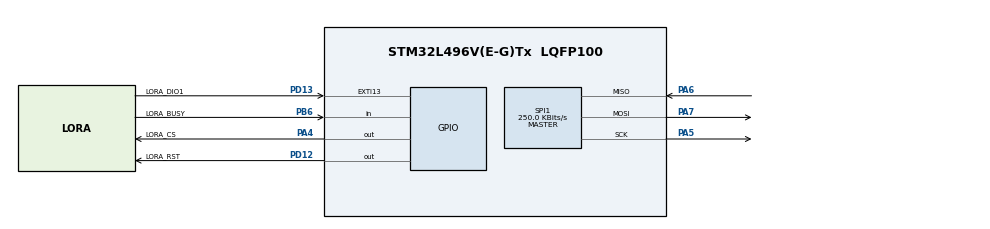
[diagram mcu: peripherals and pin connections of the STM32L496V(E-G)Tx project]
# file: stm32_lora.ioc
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FREERTOS.Tasks01=OBCTask,24,2048,StartOBCTask,Default,NULL,Dynamic,NULL,NULL
FREERTOS.configTOTAL_HEAP_SIZE=65536
FREERTOS.configUSE_NEWLIB_REENTRANT=1
Mcu.Family=STM32L4
Mcu.Name=STM32L496V(E-G)Tx
Mcu.Package=LQFP100
NVIC.EXTI15_10_IRQn=true\:5\:0\:false\:false\:true\:true\:true\:true\:true
NVIC.PriorityGroup=NVIC_PRIORITYGROUP_4
NVIC.TIM6_DAC_IRQn=true\:15\:0\:false\:false\:true\:false\:false\:true\:true
NVIC.TimeBase=TIM6_DAC_IRQn
NVIC.TimeBaseIP=TIM6
PA13\ (JTMS/SWDIO).Mode=Trace_Asynchronous_SW
PA13\ (JTMS/SWDIO).Signal=SYS_JTMS-SWDIO
PA14\ (JTCK/SWCLK).Mode=Trace_Asynchronous_SW
PA14\ (JTCK/SWCLK).Signal=SYS_JTCK-SWCLK
PA4.GPIO_Label=LORA_CS
PA4.GPIO_Speed=GPIO_SPEED_FREQ_HIGH
PA4.PinState=GPIO_PIN_SET
PA4.Signal=GPIO_Output
PA5.Mode=Full_Duplex_Master
PA5.Signal=SPI1_SCK
PA6.Mode=Full_Duplex_Master
PA6.Signal=SPI1_MISO
PA7.Mode=Full_Duplex_Master
PA7.Signal=SPI1_MOSI
PB3\ (JTDO/TRACESWO).Mode=Trace_Asynchronous_SW
PB3\ (JTDO/TRACESWO).Signal=SYS_JTDO-SWO
PB6.GPIO_Label=LORA_BUSY
PB6.Signal=GPIO_Input
PD12.GPIO_Label=LORA_RST
PD12.PinState=GPIO_PIN_SET
PD12.Signal=GPIO_Output
PD13.GPIO_Label=LORA_DIO1
PD13.Signal=GPXTI13
ProjectManager.HeapSize=0x200
ProjectManager.StackSize=0x400
ProjectManager.TargetToolchain=STM32CubeIDE
RCC.HSE_VALUE=8000000
RCC.HSI48_VALUE=48000000
RCC.HSI_VALUE=16000000
RCC.LSE_VALUE=32768
RCC.MSI_VALUE=4000000
RCC.VCOOutputFreq_Value=32000000
SPI1.BaudRatePrescaler=SPI_BAUDRATEPRESCALER_16
SPI1.CLKPhase=SPI_PHASE_1EDGE
SPI1.CalculateBaudRate=250.0 KBits/s
SPI1.DataSize=SPI_DATASIZE_8BIT
SPI1.Direction=SPI_DIRECTION_2LINES
SPI1.Mode=SPI_MODE_MASTER
SPI1.NSSPMode=SPI_NSS_PULSE_DISABLE
SPI1.VirtualType=VM_MASTER
VP_FREERTOS_VS_CMSIS_V2.Mode=CMSIS_V2
VP_SYS_VS_tim6.Mode=TIM6
board=custom

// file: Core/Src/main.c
/* USER CODE BEGIN Header */
/**
  ******************************************************************************
  * @file           : main.c
  * @brief          : Main program body
  ******************************************************************************
  * @attention
  *
  * Copyright (c) 2026 STMicroelectronics.
  * All rights reserved.
  *
  * This software is licensed under terms that can be found in the LICENSE file
  * in the root directory of this software component.
  * If no LICENSE file comes with this software, it is provided AS-IS.
  *
  ******************************************************************************
  */
/* USER CODE END Header */
#include "main.h"
#include "cmsis_os.h"

/* USER CODE BEGIN Includes */
#include "COMMS.h"
/* USER CODE END Includes */

SPI_HandleTypeDef hspi1;

/* Definitions for OBCTask */
osThreadId_t OBCTaskHandle;
const osThreadAttr_t OBCTask_attributes = {
  .name = "OBCTask",
  .stack_size = 2048 * 4,
  .priority = (osPriority_t) osPriorityNormal,
};

void SystemClock_Config(void);
static void MX_GPIO_Init(void);
static void MX_SPI1_Init(void);
void StartOBCTask(void *argument);

/* USER CODE BEGIN 0 */
#include <stdio.h>

int _write(int file, char *ptr, int len)
{
    for (int i = 0; i < len; i++) {
        ITM_SendChar((*ptr++));
    }
    return len;
}
/* USER CODE END 0 */

int main(void)
{

  /* MCU Configuration--------------------------------------------------------*/

  /* Reset of all peripherals, Initializes the Flash interface and the Systick. */
  HAL_Init();

  /* Configure the system clock */
  SystemClock_Config();

  /* Initialize all configured peripherals */
  MX_GPIO_Init();
  MX_SPI1_Init();
  /* USER CODE BEGIN 2 */
  // --- SPI LOOPBACK TEST ---
  /*
	printf("Starting SPI Loopback Test...\r\n");
	uint8_t tx_data = 0xA5;
	uint8_t rx_data = 0x00;

	// CS must be high or disconnected for this test, but doesn't matter for loopback logic
	HAL_GPIO_WritePin(LORA_CS_GPIO_Port, LORA_CS_Pin, GPIO_PIN_SET);

	// Send 0xA5 and expect 0xA5 back
	if (HAL_SPI_TransmitReceive(&hspi1, &tx_data, &rx_data, 1, 100) == HAL_OK) {
		if (rx_data == 0xA5) {
			printf("SPI LOOPBACK SUCCESS! STM32 is fine.\r\n");
		} else {
			printf("SPI LOOPBACK FAILED! Sent A5, Got %02X. Check Prescaler/GPIO config.\r\n", rx_data);
		}
	} else {
		printf("SPI HAL ERROR.\r\n");
	}
	*/
  /* USER CODE END 2 */

  /* Init scheduler */
  osKernelInitialize();

  /* Create the thread(s) */
  /* creation of OBCTask */
  OBCTaskHandle = osThreadNew(StartOBCTask, NULL, &OBCTask_attributes);

  /* Start scheduler */
  osKernelStart();

  /* We should never get here as control is now taken by the scheduler */

  /* Infinite loop */
  while (1)
  {

  }
}

void SystemClock_Config(void)
{
  RCC_OscInitTypeDef RCC_OscInitStruct = {0};
  RCC_ClkInitTypeDef RCC_ClkInitStruct = {0};

  /** Configure the main internal regulator output voltage
  */
  if (HAL_PWREx_ControlVoltageScaling(PWR_REGULATOR_VOLTAGE_SCALE1) != HAL_OK)
  {
    Error_Handler();
  }

  /** Initializes the RCC Oscillators according to the specified parameters
  * in the RCC_OscInitTypeDef structure.
  */
  RCC_OscInitStruct.OscillatorType = RCC_OSCILLATORTYPE_MSI;
  RCC_OscInitStruct.MSIState = RCC_MSI_ON;
  RCC_OscInitStruct.MSICalibrationValue = 0;
  RCC_OscInitStruct.MSIClockRange = RCC_MSIRANGE_6;
  RCC_OscInitStruct.PLL.PLLState = RCC_PLL_NONE;
  if (HAL_RCC_OscConfig(&RCC_OscInitStruct) != HAL_OK)
  {
    Error_Handler();
  }

  /** Initializes the CPU, AHB and APB buses clocks
  */
  RCC_ClkInitStruct.ClockType = RCC_CLOCKTYPE_HCLK|RCC_CLOCKTYPE_SYSCLK
                              |RCC_CLOCKTYPE_PCLK1|RCC_CLOCKTYPE_PCLK2;
  RCC_ClkInitStruct.SYSCLKSource = RCC_SYSCLKSOURCE_MSI;
  RCC_ClkInitStruct.AHBCLKDivider = RCC_SYSCLK_DIV1;
  RCC_ClkInitStruct.APB1CLKDivider = RCC_HCLK_DIV1;
  RCC_ClkInitStruct.APB2CLKDivider = RCC_HCLK_DIV1;

  if (HAL_RCC_ClockConfig(&RCC_ClkInitStruct, FLASH_LATENCY_0) != HAL_OK)
  {
    Error_Handler();
  }
}

static void MX_SPI1_Init(void)
{

  /* SPI1 parameter configuration*/
  hspi1.Instance = SPI1;
  hspi1.Init.Mode = SPI_MODE_MASTER;
  hspi1.Init.Direction = SPI_DIRECTION_2LINES;
  hspi1.Init.DataSize = SPI_DATASIZE_8BIT;
  hspi1.Init.CLKPolarity = SPI_POLARITY_LOW;
  hspi1.Init.CLKPhase = SPI_PHASE_1EDGE;
  hspi1.Init.NSS = SPI_NSS_SOFT;
  hspi1.Init.BaudRatePrescaler = SPI_BAUDRATEPRESCALER_16;
  hspi1.Init.FirstBit = SPI_FIRSTBIT_MSB;
  hspi1.Init.TIMode = SPI_TIMODE_DISABLE;
  hspi1.Init.CRCCalculation = SPI_CRCCALCULATION_DISABLE;
  hspi1.Init.CRCPolynomial = 7;
  hspi1.Init.CRCLength = SPI_CRC_LENGTH_DATASIZE;
  hspi1.Init.NSSPMode = SPI_NSS_PULSE_DISABLE;
  if (HAL_SPI_Init(&hspi1) != HAL_OK)
  {
    Error_Handler();
  }

}

static void MX_GPIO_Init(void)
{
  GPIO_InitTypeDef GPIO_InitStruct = {0};

  /* GPIO Ports Clock Enable */
  __HAL_RCC_GPIOA_CLK_ENABLE();
  __HAL_RCC_GPIOD_CLK_ENABLE();
  __HAL_RCC_GPIOB_CLK_ENABLE();

  /*Configure GPIO pin Output Level */
  HAL_GPIO_WritePin(LORA_CS_GPIO_Port, LORA_CS_Pin, GPIO_PIN_SET);

  /*Configure GPIO pin Output Level */
  HAL_GPIO_WritePin(LORA_RST_GPIO_Port, LORA_RST_Pin, GPIO_PIN_SET);

  /*Configure GPIO pin : LORA_CS_Pin */
  GPIO_InitStruct.Pin = LORA_CS_Pin;
  GPIO_InitStruct.Mode = GPIO_MODE_OUTPUT_PP;
  GPIO_InitStruct.Pull = GPIO_NOPULL;
  GPIO_InitStruct.Speed = GPIO_SPEED_FREQ_HIGH;
  HAL_GPIO_Init(LORA_CS_GPIO_Port, &GPIO_InitStruct);

  /*Configure GPIO pin : LORA_RST_Pin */
  GPIO_InitStruct.Pin = LORA_RST_Pin;
  GPIO_InitStruct.Mode = GPIO_MODE_OUTPUT_PP;
  GPIO_InitStruct.Pull = GPIO_NOPULL;
  GPIO_InitStruct.Speed = GPIO_SPEED_FREQ_LOW;
  HAL_GPIO_Init(LORA_RST_GPIO_Port, &GPIO_InitStruct);

  /*Configure GPIO pin : LORA_DIO1_Pin */
  GPIO_InitStruct.Pin = LORA_DIO1_Pin;
  GPIO_InitStruct.Mode = GPIO_MODE_IT_RISING;
  GPIO_InitStruct.Pull = GPIO_NOPULL;
  HAL_GPIO_Init(LORA_DIO1_GPIO_Port, &GPIO_InitStruct);

  /*Configure GPIO pin : LORA_BUSY_Pin */
  GPIO_InitStruct.Pin = LORA_BUSY_Pin;
  GPIO_InitStruct.Mode = GPIO_MODE_INPUT;
  GPIO_InitStruct.Pull = GPIO_NOPULL;
  HAL_GPIO_Init(LORA_BUSY_GPIO_Port, &GPIO_InitStruct);

  /* EXTI interrupt init*/
  HAL_NVIC_SetPriority(EXTI15_10_IRQn, 5, 0);
  HAL_NVIC_EnableIRQ(EXTI15_10_IRQn);

}

void StartOBCTask(void *argument)
{
  /* USER CODE BEGIN 5 */
	/* Infinite loop */
	app_OBC_loop(argument);

	/* Infinite loop di sicurezza */
	// Se il codice arriva qui, significa che app_OBC_loop è terminata (non dovrebbe succedere)
	for(;;)
	{
		printf("ERROR: OBC loop is dead.\r\n");
		osDelay(1000);
	}
  /* USER CODE END 5 */
}

void HAL_TIM_PeriodElapsedCallback(TIM_HandleTypeDef *htim)
{
  if (htim->Instance == TIM6)
  {
    HAL_IncTick();
  }
}

void Error_Handler(void)
{
  __disable_irq();
  while (1)
  {
  }
}
